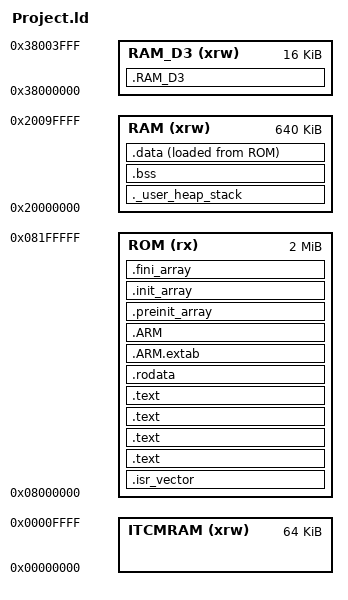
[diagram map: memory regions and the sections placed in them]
/**
 ******************************************************************************
 * @file      LinkerScript.ld
 * @author    Auto-generated by STM32CubeIDE
 *  Abstract    : Linker script for CubeIDE
 *
 *            Set heap size, stack size and stack location according
 *            to application requirements.
 *
 *            Set memory bank area and size if external memory is used
 ******************************************************************************
 * @attention
 *
 * <h2><center>&copy; Copyright (c) 2020 STMicroelectronics.
 * All rights reserved.</center></h2>
 *
 * This software component is licensed by ST under BSD 3-Clause license,
 * the "License"; You may not use this file except in compliance with the
 * License. You may obtain a copy of the License at:
 *                        opensource.org/licenses/BSD-3-Clause
 *
 ******************************************************************************
 */

/* Entry Point */
ENTRY(Reset_Handler)


_Min_Heap_Size = 590K;	/* required amount of heap  */
_Min_Stack_Size = 3K;	/* required amount of stack */

/* Memories definition */
MEMORY
{
  ITCMRAM    (xrw)   : ORIGIN = 0x00000000,   LENGTH = 64K
  RAM    (xrw)       : ORIGIN = 0x20000000,   LENGTH = 640K
  ROM    (rx)        : ORIGIN = 0x08000000,   LENGTH = 2048K 
  RAM_D3 (xrw)       : ORIGIN = 0x38000000,   LENGTH = 16K
}

/* Sections */
SECTIONS
{
  /* The startup code into "ROM" Rom type memory */
  .isr_vector (READONLY) :
  {
	PROVIDE(_sflash = .);
    . = ALIGN(4);
    KEEP(*(.isr_vector)) /* Startup code */
    . = ALIGN(4);
  } >ROM

  /* The program code and other data into "ROM" Rom type memory */
  .text (READONLY):
  {
    . = ALIGN(4);
    *(.text)           /* .text sections (code) */
    *(.text*)          /* .text* sections (code) */
    *(.glue_7)         /* glue arm to thumb code */
    *(.glue_7t)        /* glue thumb to arm code */
    *(.eh_frame)

    KEEP (*(.init))
    KEEP (*(.fini))

    . = ALIGN(4);
    _etext = .;        /* define a global symbols at end of code */
  } >ROM
  
  .text (READONLY):
  {
    . = ALIGN(4);
    st_plugin_entries = .;        /* define a global symbols ref   plugin entry */
    KEEP (*(st_plugin_entries))  /* all plugin callback*/ 
  	BYTE (0x0) ;   				  /* marker end of plugin-in list */
  	BYTE (0x0) ;    
  	BYTE (0x0) ;    
  	BYTE (0x0) ;    
  } >ROM
 
  .text (READONLY) :
  {
    . = ALIGN(4);
    _term_cmd_entries = .;        /* define a global symbols ref   term entry */
    KEEP (*(term_cmd_entries)) /* all plugin callback*/ 
  	BYTE (0x0) ;    /* marker end of plugin-in list */
  	BYTE (0x0) ;    
  	BYTE (0x0) ;    
  	BYTE (0x0) ;    
  } >ROM
  
  
  

  .text (READONLY):
  {
    . = ALIGN(4);
    algo_factory = .;        /* define a global symbols ref   term entry */
    KEEP (*(.algo_factory)) /* all plugin callback*/ 
  	BYTE (0x0) ;    /* marker end of plugin-in list */
  	BYTE (0x0) ;    
  	BYTE (0x0) ;    
  	BYTE (0x0) ;    
  } >ROM



  /* Constant data into "ROM" Rom type memory */
  .rodata (READONLY) :
  {
    . = ALIGN(4);
    *(.rodata)         /* .rodata sections (constants, strings, etc.) */
    *(.rodata*)        /* .rodata* sections (constants, strings, etc.) */
    . = ALIGN(4);
  } >ROM

  .ARM.extab (READONLY)  : { 
    . = ALIGN(4);
    *(.ARM.extab* .gnu.linkonce.armextab.*)
    . = ALIGN(4);
  } >ROM
  
  .ARM (READONLY) : {
    . = ALIGN(4);
    __exidx_start = .;
    *(.ARM.exidx*)
    __exidx_end = .;
    . = ALIGN(4);
  } >ROM

  .preinit_array (READONLY)    :
  {
    . = ALIGN(4);
    PROVIDE_HIDDEN (__preinit_array_start = .);
    KEEP (*(.preinit_array*))
    PROVIDE_HIDDEN (__preinit_array_end = .);
    . = ALIGN(4);
  } >ROM
  
  .init_array (READONLY) :
  {
    . = ALIGN(4);
    PROVIDE_HIDDEN (__init_array_start = .);
    KEEP (*(SORT(.init_array.*)))
    KEEP (*(.init_array*))
    PROVIDE_HIDDEN (__init_array_end = .);
    . = ALIGN(4);
  } >ROM
  
  .fini_array (READONLY) :
  {
    . = ALIGN(4);
    PROVIDE_HIDDEN (__fini_array_start = .);
    KEEP (*(SORT(.fini_array.*)))
    KEEP (*(.fini_array*))
    PROVIDE_HIDDEN (__fini_array_end = .);
    PROVIDE(_eflash = .);
    . = ALIGN(4);
  } >ROM

  /* Used by the startup to initialize data */
  _sidata = LOADADDR(.data);
 

  
  /* used by the startup to initialize data */
  _siRAM_D3 = LOADADDR(.RAM_D3);

  .RAM_D3 : {
  . = ALIGN(4);
  _sRAM_D3 = .;        
    . = ALIGN(4);
   _eRAM_D3 = .;        
   } >RAM_D3 

  /* User_heap_stack section, used to check that there is enough "RAM" Ram  type memory left */
  ._user_heap_stack :
  {
    . = ALIGN(8);
    PROVIDE ( _sstack = .);
    . = . + _Min_Stack_Size;
    PROVIDE ( _estack = .);
    . = ALIGN(8);
    PROVIDE(_sheap = .);
    . = . + _Min_Heap_Size;
    PROVIDE ( _eheap = .);
    . = ALIGN(8);
    PROVIDE ( end = . );
    PROVIDE ( _end = . );
  } >RAM

  /* Uninitialized data section into "RAM" Ram type memory */
  . = ALIGN(4);
  .bss :
  {
    /* This is used by the startup in order to initialize the .bss section */
    _sbss = .;         /* define a global symbol at bss start */
    __bss_start__ = _sbss;
    *(.bss)
    *(.bss*)
    *(COMMON)

    . = ALIGN(4);
    _ebss = .;         /* define a global symbol at bss end */
    __bss_end__ = _ebss;
  } >RAM

  /* Initialized data sections into "RAM" Ram type memory */
  .data : 
  {
    . = ALIGN(4);
    _sdata = .;        /* create a global symbol at data start */
    *(.data)           /* .data sections */
    *(.data*)          /* .data* sections */

    . = ALIGN(4);
    _edata = .;        /* define a global symbol at data end */
    
  } >RAM AT> ROM


  /* Remove information from the compiler libraries */
  /DISCARD/ :
  {
    libc.a ( * )
    libm.a ( * )
    libgcc.a ( * )
  }

  .ARM.attributes 0 : { *(.ARM.attributes) }
}
